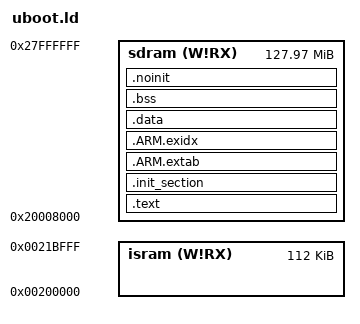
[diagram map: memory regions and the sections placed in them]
/****************************************************************************
 * boards/arm/sama5/giant-board/scripts/uboot.ld
 *
 *  Licensed to the Apache Software Foundation (ASF) under one or more
 *  contributor license agreements.  See the NOTICE file distributed with
 *  this work for additional information regarding copyright ownership.  The
 *  ASF licenses this file to you under the Apache License, Version 2.0 (the
 *  "License"); you may not use this file except in compliance with the
 *  License.  You may obtain a copy of the License at
 *
 *    http://www.apache.org/licenses/LICENSE-2.0
 *
 *  Unless required by applicable law or agreed to in writing, software
 *  distributed under the License is distributed on an "AS IS" BASIS, WITHOUT
 *  WARRANTIES OR CONDITIONS OF ANY KIND, either express or implied.  See the
 *  License for the specific language governing permissions and limitations
 *  under the License.
 *
 ****************************************************************************/

/* The SAMA5D27C-D1G has 128 KB of ISRAM beginning at virtual address 0x0020:0000.
 * This memory configuration, however, loads into the 256MB SDRAM on board
 * the SAMA5D27C-D1G which lies at 0x2000:0000.  An offset 0x00008000 is
 * reserved for used by the U-boot bootloader.
 *
 * Vectors in low memory are assumed and 16KB of ISRAM is reserved at the
 * high end of ISRAM for the page table.
 */

MEMORY
{
    isram (W!RX) : ORIGIN = 0x00200000, LENGTH = 128K - 16K
    sdram (W!RX) : ORIGIN = 0x20008000, LENGTH = 128M - 32K
}

ENTRY(entry)
ENTRY(_stext)

SECTIONS
{
    .text :
    {
        _stext = ABSOLUTE(.);
        *(.vectors)
        *(.text .text.*)
        *(.fixup)
        *(.gnu.warning)
        *(.rodata .rodata.*)
        *(.gnu.linkonce.t.*)
        *(.glue_7)
        *(.glue_7t)
        *(.got)
        *(.gcc_except_table)
        *(.gnu.linkonce.r.*)
        *(.ARM.extab*)
        *(.gnu.linkonce.armextab.*)
        _etext = ABSOLUTE(.);
    } > sdram

    .init_section :
    {
        _sinit = ABSOLUTE(.);
        *(.init_array .init_array.*)
        _einit = ABSOLUTE(.);
    } > sdram

    .ARM.extab :
    {
        *(.ARM.extab*)
    } > sdram

    /* .ARM.exidx is sorted, so has to go in its own output section.  */

    PROVIDE_HIDDEN (__exidx_start = .);
    .ARM.exidx :
    {
        *(.ARM.exidx* .gnu.linkonce.armexidx.*)
    } > sdram
    PROVIDE_HIDDEN (__exidx_end = .);

    .data :
    {
        _sdata = ABSOLUTE(.);
        *(.data .data.*)
        *(.gnu.linkonce.d.*)
        CONSTRUCTORS
        . = ALIGN(4);
        _edata = ABSOLUTE(.);
    } > sdram

    .bss :
    {
        _sbss = ABSOLUTE(.);
        *(.bss .bss.*)
        *(.gnu.linkonce.b.*)
        *(COMMON)
        . = ALIGN(4);
        _ebss = ABSOLUTE(.);
    } > sdram

    /* Uninitialized data */

    .noinit :
    {
        _snoinit = ABSOLUTE(.);
        *(.noinit*)
        _enoinit = ABSOLUTE(.);
    } > sdram

    /* Stabs debugging sections. */

    .stab 0 : { *(.stab) }
    .stabstr 0 : { *(.stabstr) }
    .stab.excl 0 : { *(.stab.excl) }
    .stab.exclstr 0 : { *(.stab.exclstr) }
    .stab.index 0 : { *(.stab.index) }
    .stab.indexstr 0 : { *(.stab.indexstr) }
    .comment 0 : { *(.comment) }
    .debug_abbrev 0 : { *(.debug_abbrev) }
    .debug_info 0 : { *(.debug_info) }
    .debug_line 0 : { *(.debug_line) }
    .debug_pubnames 0 : { *(.debug_pubnames) }
    .debug_aranges 0 : { *(.debug_aranges) }
}
